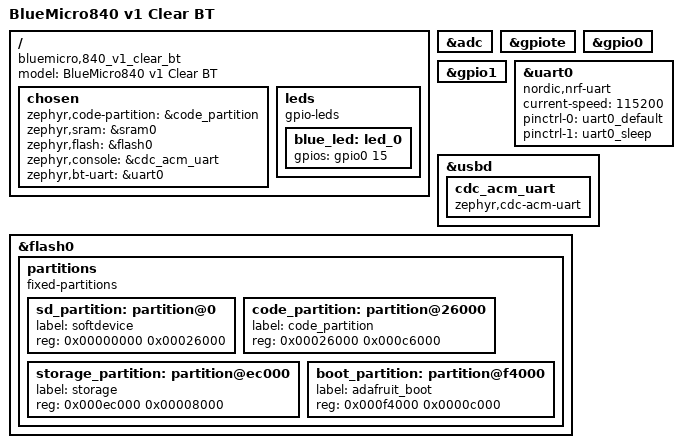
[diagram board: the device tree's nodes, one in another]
/*
 * Copyright (c) 2024 The ZMK Contributors
 * SPDX-License-Identifier: MIT
 */

/dts-v1/;
#include <nordic/nrf52840_qiaa.dtsi>
#include "bluemicro840_v1_clear_bt-pinctrl.dtsi"

/ {
    model = "BlueMicro840 v1 Clear BT";
    compatible = "bluemicro,840_v1_clear_bt";

    chosen {
        zephyr,code-partition = &code_partition;
        zephyr,sram = &sram0;
        zephyr,flash = &flash0;
        zephyr,console = &cdc_acm_uart;
        zephyr,bt-uart = &uart0;
    };

    leds {
        compatible = "gpio-leds";
        blue_led: led_0 {
            gpios = <&gpio0 15 GPIO_ACTIVE_HIGH>;
        };
    };
};

&adc {
    status = "okay";
};

&gpiote {
    status = "okay";
};

&gpio0 {
    status = "okay";
};

&gpio1 {
    status = "okay";
};

&uart0 {
    compatible = "nordic,nrf-uart";
    current-speed = <115200>;
    status = "okay";
    pinctrl-0 = <&uart0_default>;
    pinctrl-1 = <&uart0_sleep>;
    pinctrl-names = "default", "sleep";
};

&usbd {
    status = "okay";
    cdc_acm_uart: cdc_acm_uart {
        compatible = "zephyr,cdc-acm-uart";
    };
};

&flash0 {
    partitions {
        compatible = "fixed-partitions";
        #address-cells = <1>;
        #size-cells = <1>;

        sd_partition: partition@0 {
            label = "softdevice";
            reg = <0x00000000 0x00026000>;
        };
        code_partition: partition@26000 {
            label = "code_partition";
            reg = <0x00026000 0x000c6000>;
        };

        storage_partition: partition@ec000 {
            label = "storage";
            reg = <0x000ec000 0x00008000>;
        };

        boot_partition: partition@f4000 {
            label = "adafruit_boot";
            reg = <0x000f4000 0x0000c000>;
        };
    };
};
